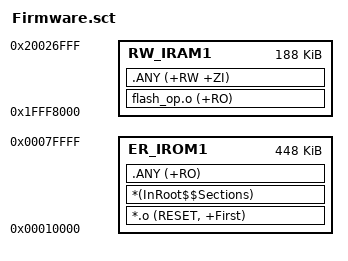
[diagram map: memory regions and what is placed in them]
; *************************************************************
; *** Scatter-Loading Description File generated by uVision ***
; *************************************************************

LR_IROM1 0x00010000 0x00070000  {    ; load region size_region (App @0x10000, boot 占 0x0-0xFFFF)
  ER_IROM1 0x00010000 0x00070000  {  ; load address = execution address
   *.o (RESET, +First)
   *(InRoot$$Sections)
   .ANY (+RO)
  }
  RW_IRAM1 0x1FFF8000 0x0002F000  {  ; RW data
    flash_op.o (+RO)
   .ANY (+RW +ZI)
  }
}

